# PIC16F15276 register map
File version: 1.0
Registers are 8-bit, read-write, reset 0x0 unless marked. A register's access mark holds for its fields unless they carry their own. Offsets are from the block's base; [hi:lo] are bit positions; {n}, {i} and the like mark numbered series.

## PORTB
Base 0x0080000D
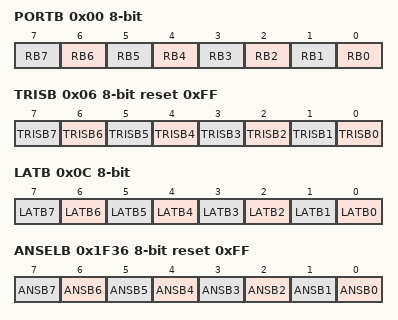
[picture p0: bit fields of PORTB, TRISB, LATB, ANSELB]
0x00 PORTB reset not defined — PORTB, data address 0x00d
  [n] RB{n} (n=0..7)
0x06 TRISB reset 0xFF — TRISB, data address 0x013
  [n] TRISB{n} (n=0..7)
0x0C LATB reset not defined — LATB, data address 0x019
  [n] LATB{n} (n=0..7)
0x1F36 ANSELB reset 0xFF — ANSELB, data address 0x1f43
  [n] ANSB{n} (n=0..7)
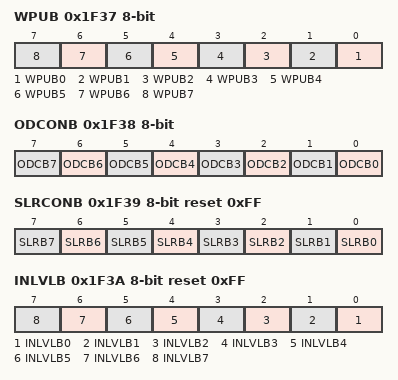
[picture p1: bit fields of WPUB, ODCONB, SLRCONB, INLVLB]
0x1F37 WPUB — WPUB, data address 0x1f44
  [n] WPUB{n} (n=0..7)
0x1F38 ODCONB — ODCONB, data address 0x1f45
  [n] ODCB{n} (n=0..7)
0x1F39 SLRCONB reset 0xFF — SLRCONB, data address 0x1f46
  [n] SLRB{n} (n=0..7)
0x1F3A INLVLB reset 0xFF — INLVLB, data address 0x1f47
  [n] INLVLB{n} (n=0..7)
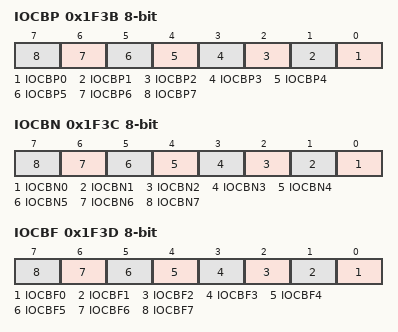
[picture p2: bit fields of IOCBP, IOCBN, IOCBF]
0x1F3B IOCBP — IOCBP, data address 0x1f48
  [n] IOCBP{n} (n=0..7)
0x1F3C IOCBN — IOCBN, data address 0x1f49
  [n] IOCBN{n} (n=0..7)
0x1F3D IOCBF — IOCBF, data address 0x1f4a
  [n] IOCBF{n} (n=0..7)

## PORTC
Base 0x0080000E
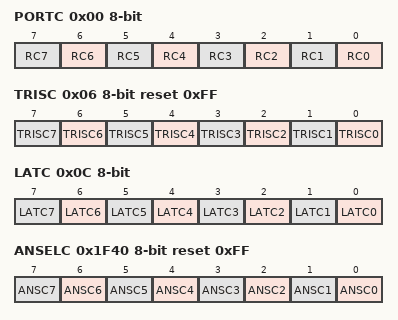
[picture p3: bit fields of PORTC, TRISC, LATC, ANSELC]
0x00 PORTC reset not defined — PORTC, data address 0x00e
  [n] RC{n} (n=0..7)
0x06 TRISC reset 0xFF — TRISC, data address 0x014
  [n] TRISC{n} (n=0..7)
0x0C LATC reset not defined — LATC, data address 0x01a
  [n] LATC{n} (n=0..7)
0x1F40 ANSELC reset 0xFF — ANSELC, data address 0x1f4e
  [n] ANSC{n} (n=0..7)
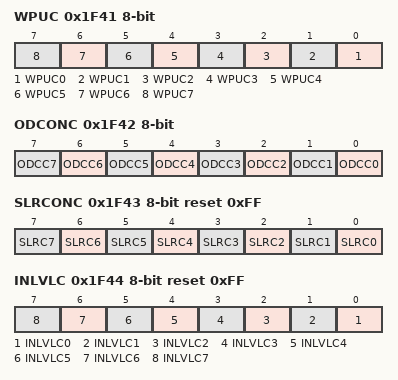
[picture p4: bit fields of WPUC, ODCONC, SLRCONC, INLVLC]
0x1F41 WPUC — WPUC, data address 0x1f4f
  [n] WPUC{n} (n=0..7)
0x1F42 ODCONC — ODCONC, data address 0x1f50
  [n] ODCC{n} (n=0..7)
0x1F43 SLRCONC reset 0xFF — SLRCONC, data address 0x1f51
  [n] SLRC{n} (n=0..7)
0x1F44 INLVLC reset 0xFF — INLVLC, data address 0x1f52
  [n] INLVLC{n} (n=0..7)
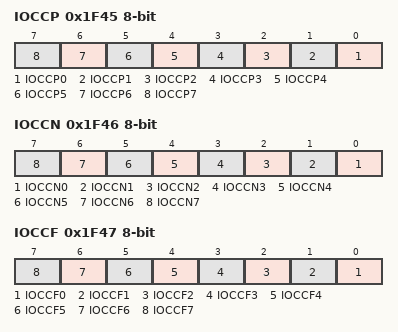
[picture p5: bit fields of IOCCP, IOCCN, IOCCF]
0x1F45 IOCCP — IOCCP, data address 0x1f53
  [n] IOCCP{n} (n=0..7)
0x1F46 IOCCN — IOCCN, data address 0x1f54
  [n] IOCCN{n} (n=0..7)
0x1F47 IOCCF — IOCCF, data address 0x1f55
  [n] IOCCF{n} (n=0..7)

## PORTD
Base 0x0080000F
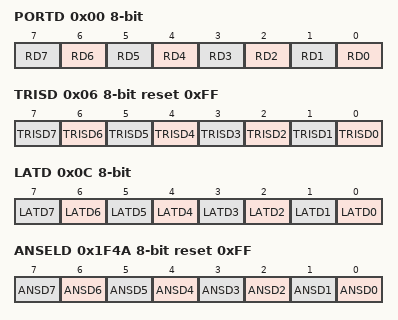
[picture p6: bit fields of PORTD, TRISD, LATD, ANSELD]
0x00 PORTD reset not defined — PORTD, data address 0x00f
  [n] RD{n} (n=0..7)
0x06 TRISD reset 0xFF — TRISD, data address 0x015
  [n] TRISD{n} (n=0..7)
0x0C LATD reset not defined — LATD, data address 0x01b
  [n] LATD{n} (n=0..7)
0x1F4A ANSELD reset 0xFF — ANSELD, data address 0x1f59
  [n] ANSD{n} (n=0..7)
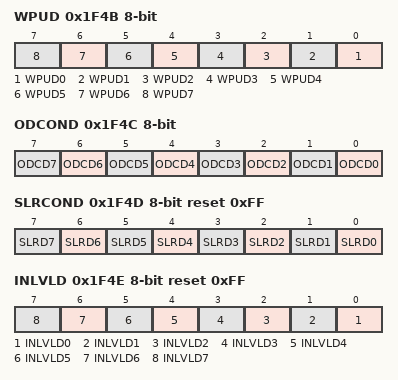
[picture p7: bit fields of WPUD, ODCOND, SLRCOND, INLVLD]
0x1F4B WPUD — WPUD, data address 0x1f5a
  [n] WPUD{n} (n=0..7)
0x1F4C ODCOND — ODCOND, data address 0x1f5b
  [n] ODCD{n} (n=0..7)
0x1F4D SLRCOND reset 0xFF — SLRCOND, data address 0x1f5c
  [n] SLRD{n} (n=0..7)
0x1F4E INLVLD reset 0xFF — INLVLD, data address 0x1f5d
  [n] INLVLD{n} (n=0..7)

## PORTE
Base 0x00800010
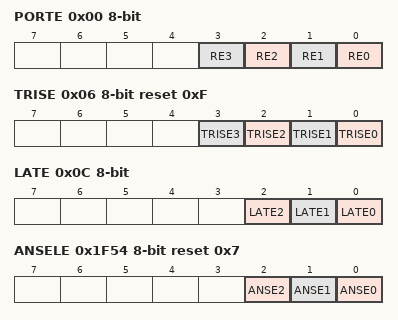
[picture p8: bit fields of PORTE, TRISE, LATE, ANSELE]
0x00 PORTE reset not defined — PORTE, data address 0x010
  [n] RE{n} (n=0..3)
0x06 TRISE reset 0xF — TRISE, data address 0x016
  [n] TRISE{n} (n=0..3)
0x0C LATE reset not defined — LATE, data address 0x01c
  [2] LATE2, [1] LATE1, [0] LATE0
0x1F54 ANSELE reset 0x7 — ANSELE, data address 0x1f64
  [2] ANSE2, [1] ANSE1, [0] ANSE0
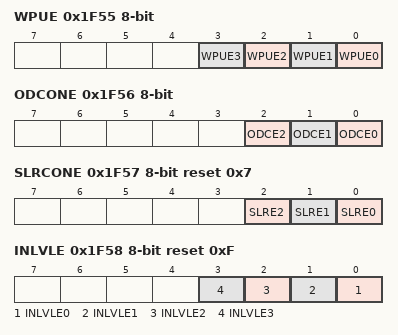
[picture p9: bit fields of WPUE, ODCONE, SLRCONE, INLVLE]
0x1F55 WPUE — WPUE, data address 0x1f65
  [n] WPUE{n} (n=0..3)
0x1F56 ODCONE — ODCONE, data address 0x1f66
  [2] ODCE2, [1] ODCE1, [0] ODCE0
0x1F57 SLRCONE reset 0x7 — SLRCONE, data address 0x1f67
  [2] SLRE2, [1] SLRE1, [0] SLRE0
0x1F58 INLVLE reset 0xF — INLVLE, data address 0x1f68
  [n] INLVLE{n} (n=0..3)
0x1F59 IOCEP — IOCEP, data address 0x1f69
  [3] IOCEP3
0x1F5A IOCEN — IOCEN, data address 0x1f6a
  [3] IOCEN3
0x1F5B IOCEF — IOCEF, data address 0x1f6b
  [3] IOCEF3

## PPS — Peripheral pin select
Base 0x00801E8F
0x00 PPSLOCK — PPSLOCK, data address 0x1e8f
  [0] PPSLOCKED
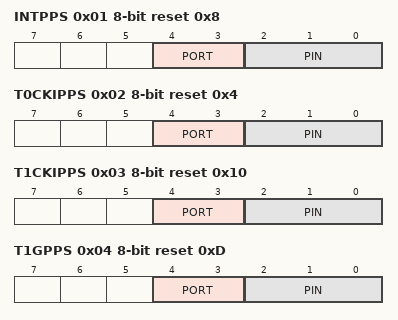
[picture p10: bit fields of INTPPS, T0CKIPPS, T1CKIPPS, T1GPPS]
0x01 INTPPS reset 0x8 — INTPPS, data address 0x1e90
  [4:3] PORT, [2:0] PIN
0x02 T0CKIPPS reset 0x4 — T0CKIPPS, data address 0x1e91
  [4:3] PORT, [2:0] PIN
0x03 T1CKIPPS reset 0x10 — T1CKIPPS, data address 0x1e92
  [4:3] PORT, [2:0] PIN
0x04 T1GPPS reset 0xD — T1GPPS, data address 0x1e93
  [4:3] PORT, [2:0] PIN
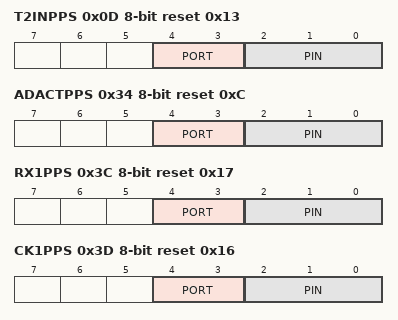
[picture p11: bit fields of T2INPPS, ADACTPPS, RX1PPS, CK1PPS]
0x0D T2INPPS reset 0x13 — T2INPPS, data address 0x1e9c
  [4:3] PORT, [2:0] PIN
0x34 ADACTPPS reset 0xC — ADACTPPS, data address 0x1ec3
  [4:3] PORT, [2:0] PIN
0x3C RX1PPS reset 0x17 — RX1PPS, data address 0x1ecb
  [4:3] PORT, [2:0] PIN
0x3D CK1PPS reset 0x16 — CK1PPS, data address 0x1ecc
  [4:3] PORT, [2:0] PIN
{0x81+i} RA{i}PPS (i=0..7) — RA{i}PPS, data address {0x1F10+i}
  [5:0] RA{i}PPS
{0x89+i} RB{i}PPS (i=0..7) — RB{i}PPS, data address {0x1F18+i}
  [5:0] RB{i}PPS
{0x91+i} RC{i}PPS (i=0..7) — RC{i}PPS, data address {0x1F20+i}
  [5:0] RC{i}PPS
{0x99+i} RD{i}PPS (i=0..7) — RD{i}PPS, data address {0x1F28+i}
  [5:0] RD{i}PPS
{0xA1+i} RE{i}PPS (i=0..2) — RE{i}PPS, data address {0x1F30+i}
  [5:0] RE{i}PPS

## REFERENCES — Voltage reference, DAC and SR latch
Base 0x0080090C
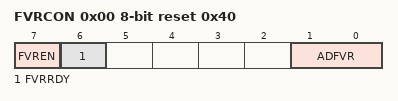
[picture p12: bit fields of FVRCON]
0x00 FVRCON reset 0x40 — FVRCON, data address 0x90c
  [7] FVREN, [6] FVRRDY, [1:0] ADFVR

## SYSTEM — Reset, watchdog and pin options
Base 0x0080080C
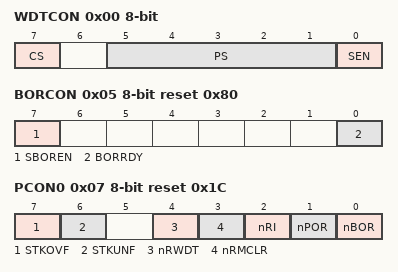
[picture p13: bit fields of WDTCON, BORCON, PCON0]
0x00 WDTCON — WDTCON, data address 0x80c
  [7] CS, [5:1] PS, [0] SEN
0x05 BORCON reset 0x80 (reset mask 0x80) — BORCON, data address 0x811
  [7] SBOREN, [0] BORRDY
0x07 PCON0 reset 0x1C (reset mask 0xDE) — PCON0, data address 0x813
  [7] STKOVF, [6] STKUNF, [4] nRWDT, [3] nRMCLR, [2] nRI, [1] nPOR, [0] nBOR
0x08 PCON1 — PCON1, data address 0x814
  [1] nMEMV

## TIMER0
Base 0x0080059C
0x00 TMR0L — TMR0L, data address 0x59c
0x01 TMR0H reset 0xFF — TMR0H, data address 0x59d
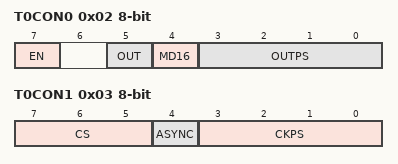
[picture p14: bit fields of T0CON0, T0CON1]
0x02 T0CON0 — T0CON0, data address 0x59e
  [7] EN, [5] OUT, [4] MD16, [3:0] OUTPS
0x03 T0CON1 — T0CON1, data address 0x59f
  [7:5] CS, [4] ASYNC, [3:0] CKPS

## TIMER1
Base 0x0080020C
0x00 TMR1L — TMR1L, data address 0x20c
0x01 TMR1H — TMR1H, data address 0x20d
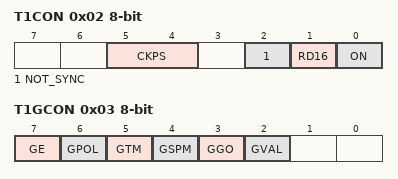
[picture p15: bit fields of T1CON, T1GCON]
0x02 T1CON — T1CON, data address 0x20e
  [5:4] CKPS, [2] NOT_SYNC, [1] RD16, [0] ON
0x03 T1GCON (reset mask 0xF8) — T1GCON, data address 0x20f
  [7] GE, [6] GPOL, [5] GTM, [4] GSPM, [3] GGO, [2] GVAL
0x04 T1GATE (reset mask 0x1F) — T1GATE, data address 0x210
  [7:0] GSS
0x05 T1CLK (reset mask 0xF) — T1CLK, data address 0x211
  [7:0] CS

## TIMER2
Base 0x0080028E
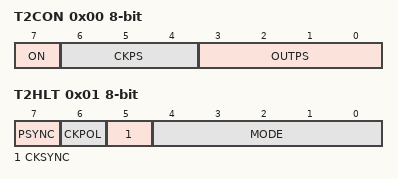
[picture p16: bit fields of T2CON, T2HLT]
0x00 T2CON — T2CON, data address 0x28e
  [7] ON, [6:4] CKPS, [3:0] OUTPS
0x01 T2HLT — T2HLT, data address 0x28f
  [7] PSYNC, [6] CKPOL, [5] CKSYNC, [4:0] MODE
0x02 T2CLKCON (reset mask 0x7) — T2CLKCON, data address 0x290
  [3:0] CS
0x03 T2RST (reset mask 0xF) — T2RST, data address 0x291
  [4:0] RSEL

## OTHER — Other registers
Base 0x0080009A
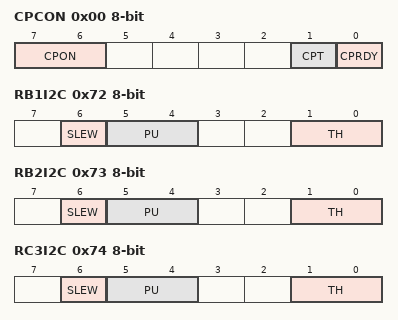
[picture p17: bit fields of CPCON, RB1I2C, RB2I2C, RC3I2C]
0x00 CPCON — CPCON, data address 0x09a
  [7:6] CPON, [1] CPT, [0] CPRDY
0x72 RB1I2C — RB1I2C, data address 0x10c
  [6] SLEW, [5:4] PU, [1:0] TH
0x73 RB2I2C — RB2I2C, data address 0x10d
  [6] SLEW, [5:4] PU, [1:0] TH
0x74 RC3I2C — RC3I2C, data address 0x10e
  [6] SLEW, [5:4] PU, [1:0] TH
0x75 RC4I2C — RC4I2C, data address 0x10f
  [6] SLEW, [5:4] PU, [1:0] TH
0x1F2 T2TMR — T2TMR, data address 0x28c
  [7:0] TMR
0x1F3 T2PR reset 0xFF — T2PR, data address 0x28d
  [7:0] PR
